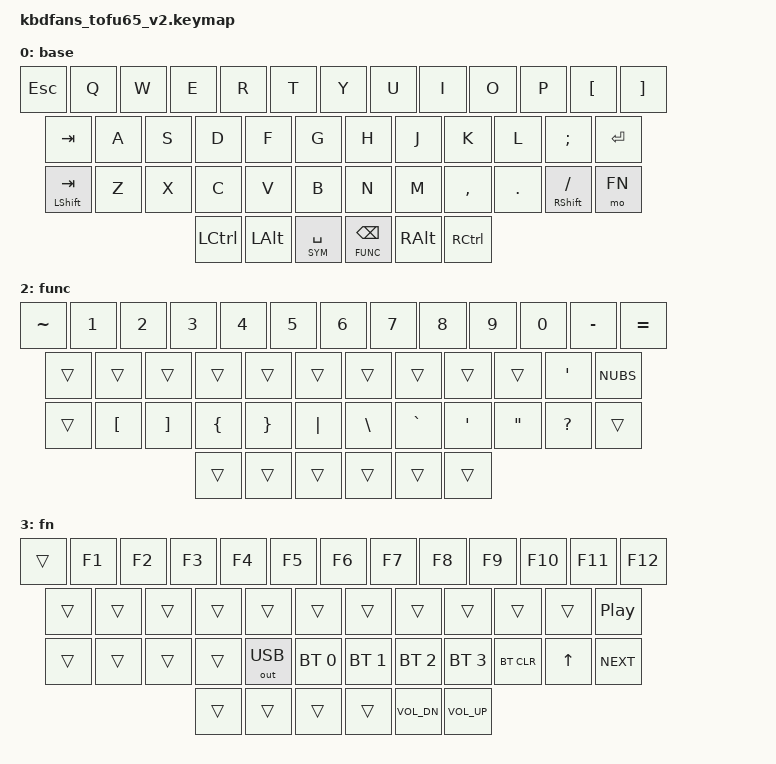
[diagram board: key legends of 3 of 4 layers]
// Copyright (c) 2024 The ZMK Contributors
// SPDX-License-Identifier: MIT

#include <behaviors.dtsi>
#include <dt-bindings/zmk/keys.h>
#include <dt-bindings/zmk/bt.h>
#include <dt-bindings/zmk/outputs.h>
#include <dt-bindings/zmk/pointing.h>

#define BASE  0
#define SYM   1
#define FUNC  2
#define FN    3

//
// ---------- Agar mini key switch positions ----------
//
// -------------------------------------------------------------------------------------------
// |  0  |  1  |  2  |  3  |  4  |  5  |  6  |  7  |  8  |  9  | 10  | 11  | 12  | 13  |
// -------------------------------------------------------------------------------------------
// |  14   | 15 |  16 |  17 |  18 |  19 |  20 |  21 |  22 |  23 |  24  |      25       |
// -------------------------------------------------------------------------------------------
// |    26    |  27 |  28 |  29 |  30 |  31 |  32 |  33 |  34 |  35 |    36    |  37   |
// -------------------------------------------------------------------------------------------
//    | 38  |   39   |          40          |          41          |   42   |  43  |
// -------------------------------------------------------------------------------------------
//


/ {
    combos {
        compatible = "zmk,combos";

        // BACKSPACE + CTRL = &sys_reset
        combo_sys_reset {
            timeout-ms = <100>;
            key-positions = <12 37>;
            bindings = <&sys_reset>;
        };

        // ENTER + CTRL = &bootloader
        combo_bootloader {
            timeout-ms = <100>;
            key-positions = <24 37>;
            bindings = <&bootloader>;
        };
    };


    keymap {
        compatible = "zmk,keymap";

        base {

// --------- Default QWERTY Layout ---------
// Layer 0 BASE
// -------------------------------------------------------------------------------------------
// | ESC |  Q  |  W  |  E  |  R  |  T  |  Y  |  U  |  I  |  O  |  P  | [ { | ] } |
// -------------------------------------------------------------------------------------------
// |  TAB   |  A  |  S  |  D  |  F  |  G  |  H  |  J  |  K  |  L  | ; : |  ENTER  |
// -------------------------------------------------------------------------------------------
// |  SHIFT  |  Z  |  X  |  C  |  V  |  B  |  N  |  M  |  ,  |  .  |   / ?   |FUNC|
// -------------------------------------------------------------------------------------------
//     | CTRL|  ALT  |        SPACE         |        BSPC        |  ALT  |  CTRL  |
// -------------------------------------------------------------------------------------------
            bindings = <
&kp ESC  &kp Q   &kp W   &kp E   &kp R   &kp T   &kp Y   &kp U   &kp I     &kp O    &kp P    &kp LBKT  &kp RBKT
&kp TAB   &kp A   &kp S   &kp D   &kp F   &kp G   &kp H   &kp J   &kp K     &kp L    &kp SEMI       &kp ENTER
&mt LSHFT TAB   &kp Z   &kp X   &kp C   &kp V   &kp B   &kp N   &kp M   &kp COMMA &kp DOT  &mt RSHFT FSLH    &mo FN
&kp LCTRL  &kp LALT        &lt SYM SPACE            &lt FUNC BSPC        &kp RALT &kp RCTRL
            >;
        };

        symbols {
// --------- Navigation & Mouse Layer ---------
// Layer 1 SYM
// -------------------------------------------------------------------------------------------
// | --- |HOME |  ↑  | END | --- |MW↓ |MW↑ |  ↑  |MBTN1|MBTN2|MBTN3| --- | --- | --- |
// -------------------------------------------------------------------------------------------
// |   ---  |  ←  |  ↓  |  →  | --- | --- |  ←  |  ↓  |  →  | --- | --- |   ---   |
// -------------------------------------------------------------------------------------------
// |   ---   |PGUP |PGDN | --- | --- | --- |MW← |MW→ | --- | --- | --- |   ---   |
// -------------------------------------------------------------------------------------------
//     | --- |  ---  |         ---          |         ---         |  ---   |  ---   |
// -------------------------------------------------------------------------------------------
            bindings = <
&trans      &kp HOME  &kp UP    &kp END   &trans  &msc SCRL_DOWN  &msc SCRL_UP  &mmv MOVE_UP    &mkp LCLK  &mkp RCLK  &mkp MCLK  &trans  &trans  &trans
&trans      &kp LEFT  &kp DOWN  &kp RIGHT &trans  &trans  &mmv MOVE_LEFT  &mmv MOVE_DOWN  &mmv MOVE_RIGHT &trans  &trans        &trans
&trans        &kp PG_UP  &kp PG_DN  &trans  &trans  &trans  &msc SCRL_LEFT  &msc SCRL_RIGHT  &trans  &trans  &trans     &trans
&trans     &trans             &trans                         &trans              &trans    &trans
            >;
        };

        func {
// --------- Numbers & Symbols Layer ---------
// Layer 2 FUNC
// -------------------------------------------------------------------------------------------
// |  ~  | 1!  | 2@  | 3#  | 4$  | 5%  | 6^  | 7&  | 8*  | 9(  | 0)  | - _ | + =  |
// -------------------------------------------------------------------------------------------
// |   ---  | --- | --- | --- | --- | --- | --- | --- | --- | --- | --- |   | \   |
// -------------------------------------------------------------------------------------------
// |   ---   |  [  |  ]  |  {  |  }  |  |  |  \  |  `  |  '  |  "  |  ?   |   ---   |
// -------------------------------------------------------------------------------------------
//     | --- |  ---  |         ---          |         ---         |  ---   |  ---   |
// -------------------------------------------------------------------------------------------
            bindings = <
&kp TILDE  &kp N1  &kp N2  &kp N3  &kp N4  &kp N5  &kp N6  &kp N7  &kp N8  &kp N9  &kp N0  &kp MINUS  &kp EQUAL
&trans      &trans    &trans  &trans    &trans    &trans     &trans     &trans    &trans    &trans    &kp SQT    &kp NUBS
&trans        &kp LBKT  &kp RBKT  &kp LBRC  &kp RBRC  &kp PIPE  &kp BSLH  &kp GRAVE  &kp SQT  &kp DQT  &kp QMARK     &trans
&trans     &trans             &trans                         &trans              &trans    &trans
            >;
        };

        fn {
// --------- F-Keys & Bluetooth Layer ---------
// Layer 3 FN
// -------------------------------------------------------------------------------------------
// | --- | F1  | F2  | F3  | F4  | F5  | F6  | F7  | F8  | F9  | F10 | F11 | F12 |
// -------------------------------------------------------------------------------------------
// |   ---  | --- | --- | --- | --- | --- | --- | --- | --- | --- | --- |   PLAY  |
// -------------------------------------------------------------------------------------------
// |   ---   | --- | --- | --- | USB | BT0 | BT1 | BT2 | BT3 |BTCLR|   ↑   |   NEXT  |
// -------------------------------------------------------------------------------------------
//     | --- |  ---  |         ---          |         ---         | VOL- | VOL+ |
// -------------------------------------------------------------------------------------------
            bindings = <
&trans  &kp F1  &kp F2  &kp F3  &kp F4  &kp F5  &kp F6  &kp F7  &kp F8  &kp F9  &kp F10  &kp F11    &kp F12
&trans   &trans  &trans  &trans  &trans  &trans  &trans  &trans  &trans  &trans  &trans       &kp C_PP
&trans     &trans  &trans  &trans  &out OUT_USB  &bt BT_SEL 0  &bt BT_SEL 1  &bt BT_SEL 2  &bt BT_SEL 3  &bt BT_CLR  &kp UP    &kp C_NEXT
&trans   &trans                 &trans                  &trans            &kp C_VOL_DN  &kp C_VOL_UP
            >;
        };
    };
};

